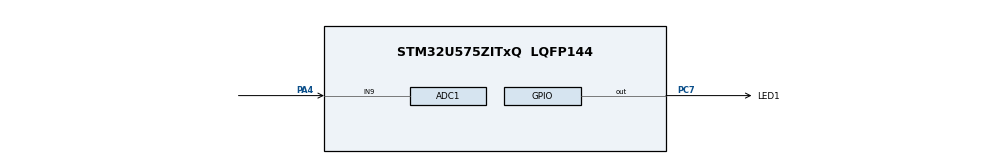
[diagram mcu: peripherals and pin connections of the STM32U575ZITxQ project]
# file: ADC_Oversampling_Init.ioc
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ADC1.Channel-0\#ChannelRegularConversion=ADC_CHANNEL_9
ADC1.ClockPrescaler=ADC_CLOCK_ASYNC_DIV2
ADC1.ContinuousConvMode=DISABLE
ADC1.EOCSelection=ADC_EOC_SINGLE_CONV
ADC1.EnableRegularConversion=ENABLE
ADC1.LeftBitShift=ADC_LEFTBITSHIFT_NONE
ADC1.NbrOfConversion=1
ADC1.NbrOfConversionFlag=1
ADC1.OffsetNumber-0\#ChannelRegularConversion=ADC_OFFSET_NONE
ADC1.Overrun=ADC_OVR_DATA_OVERWRITTEN
ADC1.OversamplingMode=ENABLE
ADC1.Rank-0\#ChannelRegularConversion=1
ADC1.Ratio=16
ADC1.Resolution=ADC_RESOLUTION_12B
ADC1.RightBitShift=ADC_RIGHTBITSHIFT_4
ADC1.SamplingTime-0\#ChannelRegularConversion=ADC_SAMPLETIME_391CYCLES_5
ADC1.master=1
CORTEX_M33_NS.userName=CORTEX_M33
Mcu.Family=STM32U5
Mcu.Name=STM32U575ZITxQ
Mcu.Package=LQFP144
NVIC.PriorityGroup=NVIC_PRIORITYGROUP_4
PA4.Mode=IN9-Single-Ended
PA4.Signal=ADC1_IN9
PC7.GPIO_Label=LED1
PC7.Signal=GPIO_Output
PWR.PowerMode=PWR_SMPS_SUPPLY
ProjectManager.HeapSize=0x200
ProjectManager.StackSize=0x400
ProjectManager.TargetToolchain=EWARM V8.50
RCC.ADCFreq_Value=16000000
RCC.AHBFreq_Value=160000000
RCC.APB1Freq_Value=160000000
RCC.APB1TimFreq_Value=160000000
RCC.APB2Freq_Value=160000000
RCC.APB2TimFreq_Value=160000000
RCC.APB3Freq_Value=160000000
RCC.CortexFreq_Value=160000000
RCC.DACCLockSelectionVirtual=RCC_DAC1CLKSOURCE_LSI
RCC.DACCLockSelectionVirtualString=RCC_DAC1CLKSOURCE_LSI
RCC.EPOD_VALUE=4000000
RCC.HCLKFreq_Value=160000000
RCC.HSE_VALUE=16000000
RCC.HSI48_VALUE=48000000
RCC.HSI_VALUE=16000000
RCC.LSE_VALUE=32768
RCC.LSIDIV_VALUE=32000
RCC.MSI_VALUE=4000000
RCC.PLLN=80
RCC.SYSCLKFreq_VALUE=160000000
RCC.SYSCLKSource=RCC_SYSCLKSOURCE_PLLCLK
RCC.USBFreq_Value=48000000
RCC.VCOOutputFreq_Value=320000000
VP_ICACHE_VS_ICACHE.Mode=DirectMappedCache
VP_LPBAMQUEUE_VS_QUEUE.Mode=QUEUEMODE
VP_LPBAM_VS_SIG1.Mode=SmartRun
VP_LPBAM_VS_SIG4.Mode=LPDMA1
VP_PWR_VS_DBSignals.Mode=DisableDeadBatterySignals
VP_PWR_VS_LPOM.Mode=PowerOptimisation
VP_PWR_VS_SECSignals.Mode=Security/Privilege
board=custom

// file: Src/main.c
/* USER CODE BEGIN Header */
/**
  ******************************************************************************
  * @file    Examples_LL/ADC/ADC_Oversampling_Init/Src/main.c
  * @author  MCD Application Team
  * @brief   This example describes how to use a ADC peripheral with
  *          ADC oversampling to perform automatically multiple
  *          ADC conversions and average computation, by ADC hardware,
  *          and therefore off-load the CPU for the equivalent task.
  *          This example is based on the STM32U5xx ADC LL API;
  *          Peripheral initialization done using LL unitary services functions.
  ******************************************************************************
  * @attention
  *
  * Copyright (c) 2021 STMicroelectronics.
  * All rights reserved.
  *
  * This software is licensed under terms that can be found in the LICENSE file
  * in the root directory of this software component.
  * If no LICENSE file comes with this software, it is provided AS-IS.
  *
  ******************************************************************************
  */
/* USER CODE END Header */
#include "main.h"

/* USER CODE BEGIN PD */

/* Definitions of ADC hardware constraints delays */
/* Note: Only ADC IP HW delays are defined in ADC LL driver driver,           */
/*       not timeout values:                                                  */
/*       Timeout values for ADC operations are dependent to device clock      */
/*       configuration (system clock versus ADC clock),                       */
/*       and therefore must be defined in user application.                   */
/*       Refer to @ref ADC_LL_EC_HW_DELAYS for description of ADC timeout     */
/*       values definition.                                                   */

  /* Timeout values for ADC operations. */
  /* (calibration, enable settling time, disable settling time, ...)          */
  /* Values defined to be higher than worst cases: low clock frequency,       */
  /* maximum prescalers.                                                      */
  /* Note: ADC channel configuration ready (ADC_CHANNEL_CONF_RDY_TIMEOUT_MS)  */
  /*       is added in CubeMx code section.                                   */
  /* Unit: ms                                                                 */
  #define ADC_CALIBRATION_TIMEOUT_MS       (   1UL)
  #define ADC_ENABLE_TIMEOUT_MS            (   1UL)
  #define ADC_DISABLE_TIMEOUT_MS           (   1UL)
  #define ADC_STOP_CONVERSION_TIMEOUT_MS   (   1UL)
  #define ADC_CONVERSION_TIMEOUT_MS        (4000UL)

  /* Delay between ADC end of calibration and ADC enable.                     */
  /* Delay estimation in CPU cycles: Case of ADC enable done                  */
  /* immediately after ADC calibration, ADC clock setting slow                */
  /* (LL_ADC_CLOCK_ASYNC_DIV32). Use a higher delay if ratio                  */
  /* (CPU clock / ADC clock) is above 32.                                     */
  #define ADC_DELAY_CALIB_ENABLE_CPU_CYCLES  (LL_ADC_DELAY_CALIB_ENABLE_ADC_CYCLES * 32)

/* Definitions of environment analog values */
  /* Value of analog reference voltage (Vref+), connected to analog voltage   */
  /* supply Vdda (unit: mV).                                                  */
  #define VDDA_APPLI                       (3300UL)

/* Definitions of data related to this example */
  /* Init variable out of expected ADC conversion data range */
  #define VAR_CONVERTED_DATA_INIT_VALUE    (__LL_ADC_DIGITAL_SCALE(ADC1, LL_ADC_RESOLUTION_12B) + 1)

  /* Init variable out of ADC expected conversion data range for data         */
  /* on 16 bits (oversampling enabled).                                       */
  #define VAR_CONVERTED_DATA_INIT_VALUE_16BITS    (0xFFFF + 1UL)

/* USER CODE END PD */

/* USER CODE BEGIN PV */

/* Variables for ADC conversion data */
__IO uint16_t uhADCxConvertedData_OVS_ratio16_shift4   = VAR_CONVERTED_DATA_INIT_VALUE;        /* ADC group regular conversion data, oversampling ratio 16 and shift 4 (data scale: 12 bits) */
__IO uint32_t uhADCxConvertedData_OVS_ratio16_shift0   = VAR_CONVERTED_DATA_INIT_VALUE_16BITS; /* ADC group regular conversion data, oversampling ratio 16 and shift 0 (data scale: 16 bits) */
__IO uint16_t uhADCxConvertedData_OVS_disabled         = VAR_CONVERTED_DATA_INIT_VALUE;        /* ADC group regular conversion data, oversampling disabled (data scale corresponds to ADC resolution: 12 bits) */

__IO float    fConvertedData_OVS_EquivalentValue12bits = 4.4f; /* Calculation of oversampling raw data to the equivalent data (from variable "uhADCxConvertedData_OVS_ratio16_shift0") to the equivalent data on 12 bits with floating point */

/* USER CODE END PV */

void SystemClock_Config(void);
static void SystemPower_Config(void);
static void MX_GPIO_Init(void);
static void MX_ICACHE_Init(void);
static void MX_ADC1_Init(void);
/* USER CODE BEGIN PFP */

void ADC_Activate(void);
void ConversionStartPoll_ADC_GrpRegular(void);
void LED_On(void);
void LED_Off(void);
void LED_Toggle(void);

/* USER CODE END PFP */

int main(void)
{

  /* MCU Configuration--------------------------------------------------------*/

  /* Reset of all peripherals, Initializes the Flash interface and the Systick. */

  /* System interrupt init*/
  NVIC_SetPriorityGrouping(NVIC_PRIORITYGROUP_4);

  /* Enable PWR clock interface */

  LL_AHB3_GRP1_EnableClock(LL_AHB3_GRP1_PERIPH_PWR);

  /* USER CODE BEGIN Init */
  /* Enable the independent analog and I/Os supply */
   LL_PWR_EnableVDDA();
   LL_PWR_EnableVDDIO2();
  /* USER CODE END Init */

  /* Configure the System Power */
  SystemPower_Config();

  /* Configure the system clock */
  SystemClock_Config();

  /* Initialize all configured peripherals */
  MX_GPIO_Init();
  MX_ICACHE_Init();
  MX_ADC1_Init();
  /* USER CODE BEGIN 2 */

  /* Activate ADC */
  /* Perform ADC activation procedure to make it ready to convert. */
  ADC_Activate();

  /* USER CODE END 2 */

  /* Infinite loop */
  /* USER CODE BEGIN WHILE */
  while (1)
  {
    /*## Step 1: ADC oversampling initial settings  ##########################*/

    /* Perform ADC group regular conversion start, poll for conversion        */
    /* completion.                                                            */
    ConversionStartPoll_ADC_GrpRegular();

    /* Retrieve ADC conversion data */
    /* (data scale with oversampling ratio 16 and shift 4 corresponds         */
    /* to ADC resolution: 12 bits)                                            */
    uhADCxConvertedData_OVS_ratio16_shift4 = LL_ADC_REG_ReadConversionData32(ADC1);

    /*## Step 2: ADC oversampling modified settings  #########################*/
    /* Modify ADC oversampling settings:                                      */
    /* - ratio: 16                                                            */
    /* - shift: 0 (no shift)                                                  */
    /* Set ADC oversampling parameters */
    LL_ADC_ConfigOverSamplingRatioShift(ADC1, LL_ADC_OVS_RATIO_16, LL_ADC_OVS_SHIFT_NONE);

    /* Perform ADC group regular conversion start, poll for conversion        */
    /* completion.                                                            */
    ConversionStartPoll_ADC_GrpRegular();

    /* Retrieve ADC conversion data */
    /* (data scale with oversampling ratio 16 and shift 0 exceeds             */
    /* ADC resolution 12 bits, data scale expected: 16 bits)                  */
    uhADCxConvertedData_OVS_ratio16_shift0 = LL_ADC_REG_ReadConversionData32(ADC1);

    /*## Step 3: ADC oversampling disabled  ##################################*/
    /* Modify ADC oversampling settings:                                      */
    /* - scope: none (oversampling disabled)                                  */
    /* Set ADC oversampling scope */
    LL_ADC_SetOverSamplingScope(ADC1, LL_ADC_OVS_DISABLE);

    /* Perform ADC group regular conversion start, poll for conversion        */
    /* completion.                                                            */
    ConversionStartPoll_ADC_GrpRegular();

    /* Retrieve ADC conversion data */
    /* (data scale with oversampling disabled corresponds                     */
    /* to ADC resolution: 12 bits)                                            */
    uhADCxConvertedData_OVS_disabled = LL_ADC_REG_ReadConversionData32(ADC1);

    /* Restore ADC oversampling initial settings for next loop:               */
    /* - scope: ADC group regular                                             */
    /* - ratio: 16                                                            */
    /* - shift: 4                                                             */
    /* Set ADC oversampling scope */
    LL_ADC_SetOverSamplingScope(ADC1, LL_ADC_OVS_GRP_REGULAR_CONTINUED);

    /* Set ADC oversampling parameters */
    LL_ADC_ConfigOverSamplingRatioShift(ADC1, LL_ADC_OVS_RATIO_16, LL_ADC_OVS_SHIFT_RIGHT_4);

    /*## Step 4: ADC conversion data evaluation  #############################*/
    /* Expected raw data: */
    /*  - Data of initial oversampling configuration (ratio 16, shift 4)      */
    /*    should be on the same scale as ADC resolution: 12 bits.             */
    /*  - Data of modified oversampling configuration (ratio 16, shift 0)     */
    /*    should exceed ADC resolution 12 bits and be on scale: 16 bits       */
    /*  - Data of oversampling disabled should be on the same scale as        */
    /*    ADC resolution: 12 bits.                                            */
    /* Expected data comparison: */
    /*  - Data of initial oversampling configuration (ratio 16, shift 4)      */
    /*    and modified oversampling configuration (ratio 16, shift 0) with    */
    /*    SW calculation of equivalent data on 12 bits with floating point    */
    /*    should be similar.                                                  */
    /*    This SW calculation is equivalent to the ADC oversampling           */
    /*    operation "shift 4".                                                */
    /*  - ADC conversion data with oversampling enabled should have less      */
    /*    variation than with oversampling disabled: oversampling is          */
    /*    equivalent to an averaging (average on 16 ADC conversions with      */
    /*    settings of this example).                                          */

    /* Note: Optionally, for this example purpose, check ADC conversion       */
    /*       data validity.                                                   */
    /* Data value should not exceed range resolution 12 bits */
    if ((uhADCxConvertedData_OVS_ratio16_shift4 > __LL_ADC_DIGITAL_SCALE(ADC1, LL_ADC_RESOLUTION_12B)) ||
        (uhADCxConvertedData_OVS_disabled > __LL_ADC_DIGITAL_SCALE(ADC1, LL_ADC_RESOLUTION_12B)))
    {
      /* Error: Data not valid */
      Error_Handler();
    }

    /* Data value should not exceed range of resolution 16 bits */
    if (uhADCxConvertedData_OVS_ratio16_shift0 > 0xFFFF)
    {
      /* Error: Data not valid */
      Error_Handler();
    }

    /* For this example purpose, calculation of oversampling raw data         */
    /* (from variable "uhADCxConvertedData_OVS_ratio16_shift0")               */
    /* to the equivalent data on 12 bits with floating point                  */
    fConvertedData_OVS_EquivalentValue12bits = (((float)uhADCxConvertedData_OVS_ratio16_shift0) / 16);

    /* Data value should not exceed range resolution 12 bits */
    if (fConvertedData_OVS_EquivalentValue12bits > __LL_ADC_DIGITAL_SCALE(ADC1, LL_ADC_RESOLUTION_12B))
    {
      /* Error: Data not valid */
      Error_Handler();
    }

    /* Toggle LED on at the end of all ADC conversions */
    LED_Toggle();

    LL_mDelay(LED_BLINK_SLOW);

    /* Note: ADC conversion data is stored into variables:                    */
    /*       - "uhADCxConvertedData_OVS_ratio16_shift4"                       */
    /*       - "uhADCxConvertedData_OVS_ratio16_shift0"                       */
    /*       - "uhADCxConvertedData_OVS_disabled"                             */
    /*       Computed data with floating point:                               */
    /*       - "fConvertedData_OVS_EquivalentValue12bits"                     */
    /*       (for debug: see variable content into watch window).             */

    /* Note: ADC conversion data can be computed to physical values           */
    /*       using ADC LL driver helper macro:                                */
    /*         uhADCxConvertedData_Voltage_mVolt                              */
    /*         = __LL_ADC_CALC_DATA_TO_VOLTAGE(VDDA_APPLI,                    */
    /*                                         uhADCxConvertedData),          */
    /*                                         LL_ADC_RESOLUTION_12B)         */

    /* USER CODE END WHILE */

  }
}

void SystemClock_Config(void)
{
  LL_FLASH_SetLatency(LL_FLASH_LATENCY_4);
  while(LL_FLASH_GetLatency()!= LL_FLASH_LATENCY_4)
  {
  }

  LL_PWR_SetRegulVoltageScaling(LL_PWR_REGU_VOLTAGE_SCALE1);
  while (LL_PWR_IsActiveFlag_VOS() == 0)
  {
  }
  LL_RCC_HSI_Enable();

   /* Wait till HSI is ready */
  while(LL_RCC_HSI_IsReady() != 1)
  {
  }

  LL_RCC_HSI_SetCalibTrimming(16);
  LL_RCC_MSIS_Enable();

   /* Wait till MSIS is ready */
  while(LL_RCC_MSIS_IsReady() != 1)
  {
  }

  LL_RCC_MSI_EnableRangeSelection();
  LL_RCC_MSIS_SetRange(LL_RCC_MSISRANGE_4);
  LL_RCC_MSI_SetCalibTrimming(16, LL_RCC_MSI_OSCILLATOR_1);
  LL_RCC_PLL1_ConfigDomain_SYS(LL_RCC_PLL1SOURCE_MSIS, 1, 80, 2);
  LL_RCC_PLL1_EnableDomain_SYS();
  LL_RCC_SetPll1EPodPrescaler(LL_RCC_PLL1MBOOST_DIV_1);
  LL_RCC_PLL1_SetVCOInputRange(LL_RCC_PLLINPUTRANGE_4_8);
  LL_RCC_PLL1_Enable();

   /* Wait till PLL is ready */
  while(LL_RCC_PLL1_IsReady() != 1)
  {
  }

   /* Intermediate AHB prescaler 2 when target frequency clock is higher than 80 MHz */
  LL_RCC_SetAHBPrescaler(LL_RCC_SYSCLK_DIV_2);

  LL_RCC_SetSysClkSource(LL_RCC_SYS_CLKSOURCE_PLL1);

   /* Wait till System clock is ready */
  while(LL_RCC_GetSysClkSource() != LL_RCC_SYS_CLKSOURCE_STATUS_PLL1)
  {
  }

  /* Insure 1us transition state at intermediate medium speed clock*/
  for (__IO uint32_t i = (160 >> 1); i !=0; i--);

  LL_RCC_SetAHBPrescaler(LL_RCC_SYSCLK_DIV_1);
  LL_RCC_SetAPB1Prescaler(LL_RCC_APB1_DIV_1);
  LL_RCC_SetAPB2Prescaler(LL_RCC_APB2_DIV_1);
  LL_RCC_SetAPB3Prescaler(LL_RCC_APB3_DIV_1);

  LL_Init1msTick(160000000);

  LL_SetSystemCoreClock(160000000);
}

/**
  * @brief Power Configuration
  * @retval None
  */
static void SystemPower_Config(void)
{

  /*
   * Disable the internal Pull-Up in Dead Battery pins of UCPD peripheral
   */
  LL_PWR_DisableUCPDDeadBattery();

  /*
   * Switch to SMPS regulator instead of LDO
   */
  LL_PWR_SetRegulatorSupply(LL_PWR_SMPS_SUPPLY);

  while(LL_PWR_IsActiveFlag_REGULATOR()!=1)
  {
  }
}

static void MX_ADC1_Init(void)
{

  LL_ADC_CommonInitTypeDef ADC_CommonInitStruct = {0};
  LL_ADC_InitTypeDef ADC_InitStruct = {0};
  LL_ADC_REG_InitTypeDef ADC_REG_InitStruct = {0};

  LL_GPIO_InitTypeDef GPIO_InitStruct = {0};

  LL_RCC_SetADCDACClockSource(LL_RCC_ADCDAC_CLKSOURCE_HSI);

  /* Peripheral clock enable */
  LL_AHB2_GRP1_EnableClock(LL_AHB2_GRP1_PERIPH_ADC12);

  LL_AHB2_GRP1_EnableClock(LL_AHB2_GRP1_PERIPH_GPIOA);
  /**ADC1 GPIO Configuration
  PA4   ------> ADC1_IN9
  */
  GPIO_InitStruct.Pin = LL_GPIO_PIN_4;
  GPIO_InitStruct.Mode = LL_GPIO_MODE_ANALOG;
  GPIO_InitStruct.Pull = LL_GPIO_PULL_NO;
  LL_GPIO_Init(GPIOA, &GPIO_InitStruct);

  /** Common config
  */
  LL_ADC_ConfigOverSamplingRatioShift(ADC1, 16, LL_ADC_OVS_SHIFT_RIGHT_4);
  LL_ADC_SetOverSamplingDiscont(ADC1, LL_ADC_OVS_REG_CONT);
  LL_ADC_SetTriggerFrequencyMode(ADC1, LL_ADC_TRIGGER_FREQ_HIGH);
  ADC_CommonInitStruct.CommonClock = LL_ADC_CLOCK_ASYNC_DIV2;
  LL_ADC_CommonInit(__LL_ADC_COMMON_INSTANCE(ADC1), &ADC_CommonInitStruct);
  ADC_InitStruct.Resolution = LL_ADC_RESOLUTION_12B;
  ADC_InitStruct.LowPowerMode = LL_ADC_LP_MODE_NONE;
  ADC_InitStruct.LeftBitShift = LL_ADC_LEFT_BIT_SHIFT_NONE;
  LL_ADC_Init(ADC1, &ADC_InitStruct);
  LL_ADC_SetGainCompensation(ADC1, 0);
  ADC_REG_InitStruct.TriggerSource = LL_ADC_REG_TRIG_SOFTWARE;
  ADC_REG_InitStruct.SequencerLength = LL_ADC_REG_SEQ_SCAN_DISABLE;
  ADC_REG_InitStruct.SequencerDiscont = LL_ADC_REG_SEQ_DISCONT_DISABLE;
  ADC_REG_InitStruct.ContinuousMode = LL_ADC_REG_CONV_SINGLE;
  ADC_REG_InitStruct.Overrun = LL_ADC_REG_OVR_DATA_OVERWRITTEN;
  ADC_REG_InitStruct.DataTransferMode = LL_ADC_REG_DR_TRANSFER;
  LL_ADC_REG_Init(ADC1, &ADC_REG_InitStruct);
  LL_ADC_SetOverSamplingScope(ADC1, LL_ADC_OVS_GRP_REGULAR_CONTINUED);

  /* Disable ADC deep power down (enabled by default after reset state) */
  LL_ADC_DisableDeepPowerDown(ADC1);
  /* Enable ADC internal voltage regulator */
  LL_ADC_EnableInternalRegulator(ADC1);
  /* Delay for ADC internal voltage regulator stabilization. */
  /* Compute number of CPU cycles to wait for, from delay in us. */
  /* Note: Variable divided by 2 to compensate partially */
  /* CPU processing cycles (depends on compilation optimization). */
  /* Note: If system core clock frequency is below 200kHz, wait time */
  /* is only a few CPU processing cycles. */
  __IO uint32_t wait_loop_index;
  wait_loop_index = ((LL_ADC_DELAY_INTERNAL_REGUL_STAB_US * (SystemCoreClock / (100000 * 2))) / 10);
  while(wait_loop_index != 0)
  {
    wait_loop_index--;
  }

  /** Configure Regular Channel
  */
  LL_ADC_SetChannelSingleDiff(ADC1, LL_ADC_CHANNEL_9, LL_ADC_SINGLE_ENDED);
  LL_ADC_REG_SetSequencerRanks(ADC1, LL_ADC_REG_RANK_1, LL_ADC_CHANNEL_9);
  LL_ADC_SetChannelSamplingTime(ADC1, LL_ADC_CHANNEL_9, LL_ADC_SAMPLINGTIME_391CYCLES_5);
  LL_ADC_SetChannelPreselection(ADC1, LL_ADC_CHANNEL_9);
  /* USER CODE BEGIN ADC1_Init 2 */

  /* Configuration of ADC interruptions */
  /* Enable interruption ADC group regular overrun */
  LL_ADC_EnableIT_OVR(ADC1);

  /* USER CODE END ADC1_Init 2 */

}

static void MX_ICACHE_Init(void)
{

  /** Enable instruction cache in 1-way (direct mapped cache)
  */
  LL_ICACHE_SetMode(LL_ICACHE_1WAY);
  LL_ICACHE_Enable();

}

static void MX_GPIO_Init(void)
{
  LL_GPIO_InitTypeDef GPIO_InitStruct = {0};

  /* GPIO Ports Clock Enable */
  LL_AHB2_GRP1_EnableClock(LL_AHB2_GRP1_PERIPH_GPIOA);
  LL_AHB2_GRP1_EnableClock(LL_AHB2_GRP1_PERIPH_GPIOC);

  /**/
  LL_GPIO_ResetOutputPin(LED1_GPIO_Port, LED1_Pin);

  /**/
  GPIO_InitStruct.Pin = LED1_Pin;
  GPIO_InitStruct.Mode = LL_GPIO_MODE_OUTPUT;
  GPIO_InitStruct.Speed = LL_GPIO_SPEED_FREQ_LOW;
  GPIO_InitStruct.OutputType = LL_GPIO_OUTPUT_PUSHPULL;
  GPIO_InitStruct.Pull = LL_GPIO_PULL_NO;
  LL_GPIO_Init(LED1_GPIO_Port, &GPIO_InitStruct);

}

/* USER CODE BEGIN 4 */

/**
  * @brief  Perform ADC activation procedure to make it ready to convert
  *         (ADC instance: ADC1).
  * @param  None
  * @retval None
  */
void ADC_Activate(void)
{
  __IO uint32_t wait_loop_index = 0U;
  #if (USE_TIMEOUT == 1)
  uint32_t Timeout = 0U; /* Variable used for timeout management */
  #endif /* USE_TIMEOUT */

  /*## Operation on ADC hierarchical scope: ADC instance #####################*/

  /* Note: Hardware constraint (refer to description of the functions         */
  /*       below):                                                            */
  /*       On this STM32 series, setting of these features is conditioned to  */
  /*       ADC state:                                                         */
  /*       ADC must be disabled.                                              */
  /* Note: In this example, all these checks are not necessary but are        */
  /*       implemented anyway to show the best practice usages                */
  /*       corresponding to reference manual procedure.                       */
  /*       Software can be optimized by removing some of these checks, if     */
  /*       they are not relevant considering previous settings and actions    */
  /*       in user application.                                               */
  if (LL_ADC_IsEnabled(ADC1) == 0)
  {
    /* Run ADC self calibration */
    LL_ADC_StartCalibration(ADC1, LL_ADC_CALIB_OFFSET);

    /* Poll for ADC effectively calibrated */
    #if (USE_TIMEOUT == 1)
    Timeout = ADC_CALIBRATION_TIMEOUT_MS;
    #endif /* USE_TIMEOUT */

    while (LL_ADC_IsCalibrationOnGoing(ADC1) != 0)
    {
    #if (USE_TIMEOUT == 1)
      /* Check Systick counter flag to decrement the time-out value */
      if (LL_SYSTICK_IsActiveCounterFlag())
      {
        if(Timeout-- == 0)
        {
          /* Error: Time-out */
          Error_Handler();
        }
      }
    #endif /* USE_TIMEOUT */
    }

    /* Delay between ADC end of calibration and ADC enable.                   */
    /* Note: Variable divided by 2 to compensate partially                    */
    /*       CPU processing cycles (depends on compilation optimization).     */
    wait_loop_index = (ADC_DELAY_CALIB_ENABLE_CPU_CYCLES >> 1);
    while(wait_loop_index != 0)
    {
      wait_loop_index--;
    }

    /* Enable ADC */
    LL_ADC_Enable(ADC1);

    /* Poll for ADC ready to convert */
    #if (USE_TIMEOUT == 1)
    Timeout = ADC_ENABLE_TIMEOUT_MS;
    #endif /* USE_TIMEOUT */

    while (LL_ADC_IsActiveFlag_ADRDY(ADC1) == 0)
    {
    #if (USE_TIMEOUT == 1)
      /* Check Systick counter flag to decrement the time-out value */
      if (LL_SYSTICK_IsActiveCounterFlag())
      {
        if(Timeout-- == 0)
        {
          /* Error: Time-out */
          Error_Handler();
        }
      }
    #endif /* USE_TIMEOUT */
    }

    /* Note: ADC flag ADRDY is not cleared here to be able to check ADC       */
    /*       status afterwards.                                               */
    /*       This flag should be cleared at ADC Deactivation, before a new    */
    /*       ADC activation, using function "LL_ADC_ClearFlag_ADRDY()".       */
  }

  /*## Operation on ADC hierarchical scope: ADC group regular ################*/
  /* Note: No operation on ADC group regular performed here.                  */
  /*       ADC group regular conversions to be performed after this function  */
  /*       using function:                                                    */
  /*       "LL_ADC_REG_StartConversion();"                                    */

  /*## Operation on ADC hierarchical scope: ADC group injected ###############*/
  /* Note: No operation on ADC group injected performed here.                 */
  /*       ADC group injected conversions to be performed after this function */
  /*       using function:                                                    */
  /*       "LL_ADC_INJ_StartConversion();"                                    */

}

/**
  * @brief  Perform ADC group regular conversion start, poll for conversion
  *         completion.
  *         (ADC instance: ADC1).
  * @note   This function does not perform ADC group regular conversion stop:
  *         intended to be used with ADC in single mode, trigger SW start
  *         (only 1 ADC conversion done at each trigger, no conversion stop
  *         needed).
  *         In case of continuous mode or conversion trigger set to
  *         external trigger, ADC group regular conversion stop must be added
  *         after polling for conversion data.
  * @param  None
  * @retval None
  */
void ConversionStartPoll_ADC_GrpRegular(void)
{
  #if (USE_TIMEOUT == 1)
  uint32_t Timeout = 0U; /* Variable used for timeout management */
  #endif /* USE_TIMEOUT */

  /* Start ADC group regular conversion */
  /* Note: Hardware constraint (refer to description of the function          */
  /*       below):                                                            */
  /*       On this STM32 series, setting of this feature is conditioned to    */
  /*       ADC state:                                                         */
  /*       ADC must be enabled without conversion on going on group regular,  */
  /*       without ADC disable command on going.                              */
  /* Note: In this example, all these checks are not necessary but are        */
  /*       implemented anyway to show the best practice usages                */
  /*       corresponding to reference manual procedure.                       */
  /*       Software can be optimized by removing some of these checks, if     */
  /*       they are not relevant considering previous settings and actions    */
  /*       in user application.                                               */
  if ((LL_ADC_IsEnabled(ADC1) == 1)               &&
      (LL_ADC_IsDisableOngoing(ADC1) == 0)        &&
      (LL_ADC_REG_IsConversionOngoing(ADC1) == 0)   )
  {
    LL_ADC_REG_StartConversion(ADC1);
  }
  else
  {
    /* Error: ADC conversion start could not be performed */
    Error_Handler();
  }

  #if (USE_TIMEOUT == 1)
  Timeout = ADC_UNITARY_CONVERSION_TIMEOUT_MS;
  #endif /* USE_TIMEOUT */

  while (LL_ADC_IsActiveFlag_EOC(ADC1) == 0)
  {
  #if (USE_TIMEOUT == 1)
    /* Check Systick counter flag to decrement the time-out value */
    if (LL_SYSTICK_IsActiveCounterFlag())
    {
      if(Timeout-- == 0)
      {
        Error_Handler();
      }
    }
  #endif /* USE_TIMEOUT */
  }

  /* Clear flag ADC group regular end of unitary conversion */
  /* Note: This action is not needed here, because flag ADC group regular   */
  /*       end of unitary conversion is cleared automatically when          */
  /*       software reads conversion data from ADC data register.           */
  /*       Nevertheless, this action is done anyway to show how to clear    */
  /*       this flag, needed if conversion data is not always read          */
  /*       or if group injected end of unitary conversion is used (for      */
  /*       devices with group injected available).                          */
  LL_ADC_ClearFlag_EOC(ADC1);

}

/**
  * @brief  Turn-on LED1.
  * @param  None
  * @retval None
  */
void LED_On(void)
{
  /* Turn LED on */
  LL_GPIO_SetOutputPin(LED1_GPIO_Port, LED1_Pin);
}

/**
  * @brief  Turn-off LED1.
  * @param  None
  * @retval None
  */
void LED_Off(void)
{
  /* Turn LED off */
  LL_GPIO_ResetOutputPin(LED1_GPIO_Port, LED1_Pin);
}

/**
  * @brief  Toggle LED1.
  * @param  None
  * @retval None
  */
void LED_Toggle(void)
{
  /* Turn LED off */
  LL_GPIO_TogglePin(LED1_GPIO_Port, LED1_Pin);
}

/******************************************************************************/
/*   USER IRQ HANDLER TREATMENT                                               */
/******************************************************************************/

/* USER CODE END 4 */

void Error_Handler(void)
{
  /* USER CODE BEGIN Error_Handler_Debug */
  /* User can add his own implementation to report the HAL error return state */

  /* Turn on LED and remain in infinite loop */
  while (1)
  {
    LED_On();
  }
  /* USER CODE END Error_Handler_Debug */
}
